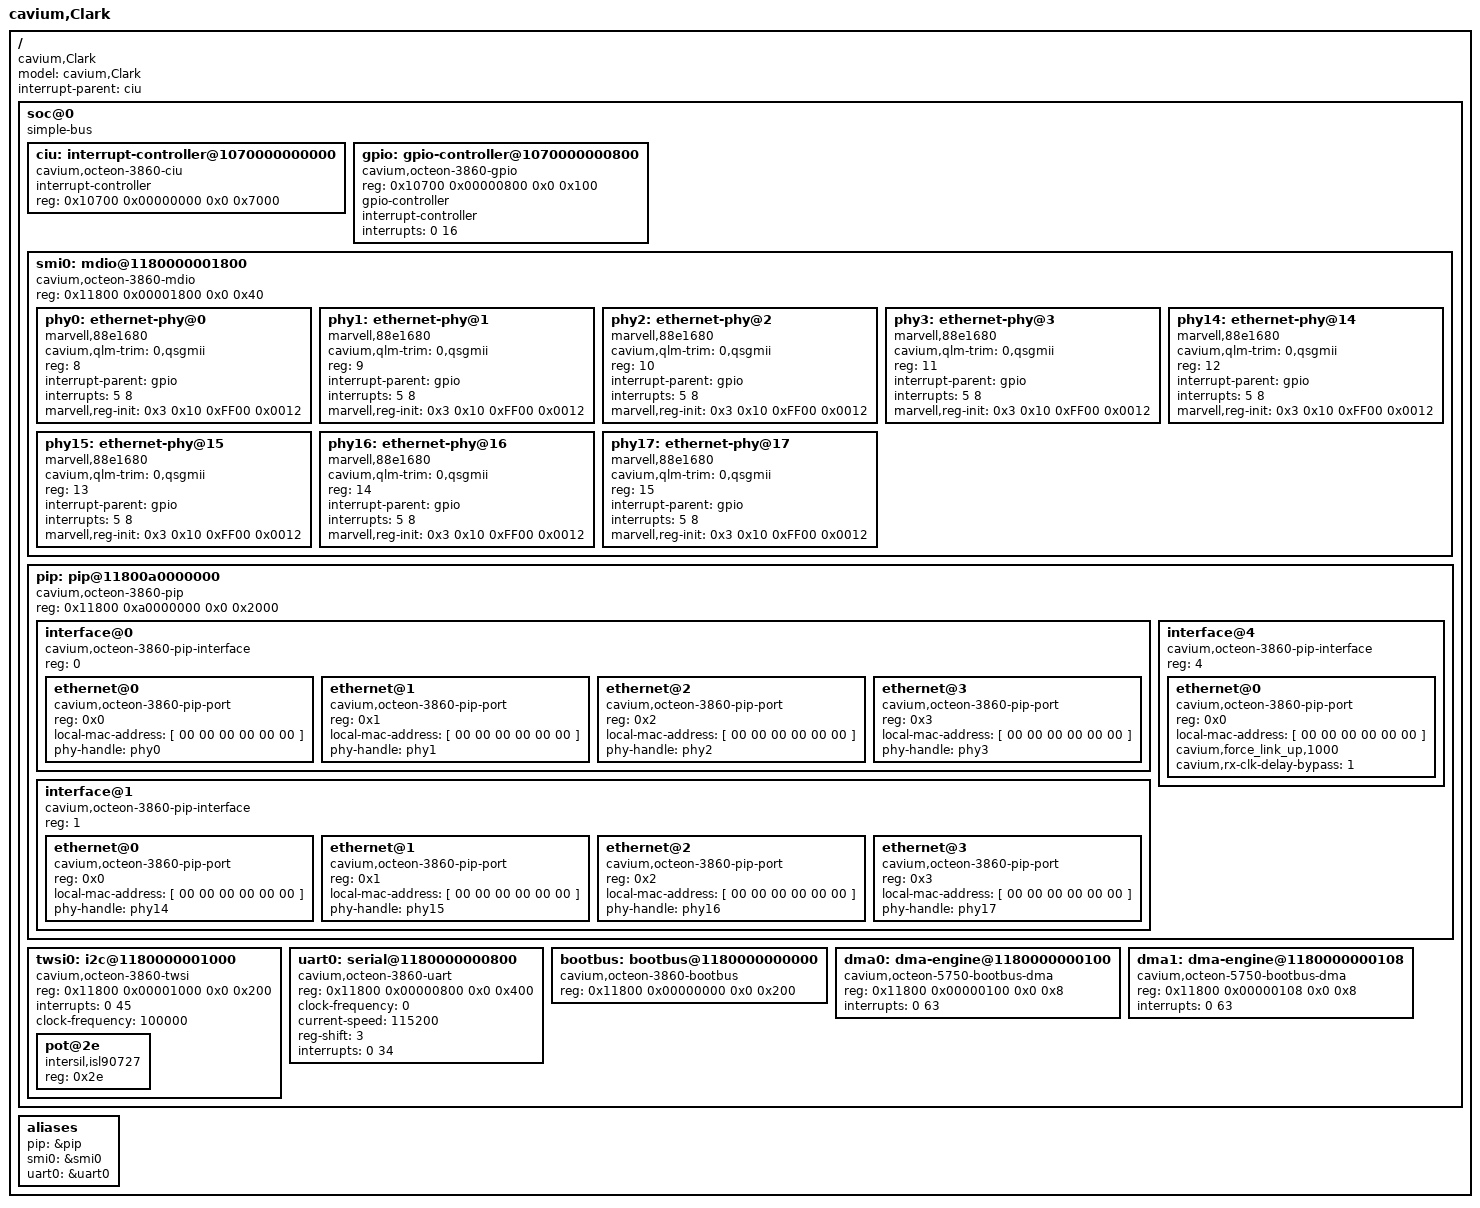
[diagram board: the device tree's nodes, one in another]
/dts-v1/;
/*
 * Cavium, Inc. Clark board
 */
/ {
	model = "cavium,Clark";
	compatible = "cavium,Clark";
	#address-cells = <2>;
	#size-cells = <2>;
	interrupt-parent = <&ciu>;

	soc@0 {
		compatible = "simple-bus";
		#address-cells = <2>;
		#size-cells = <2>;
		ranges; /* Direct mapping */

		ciu: interrupt-controller@1070000000000 {
			compatible = "cavium,octeon-3860-ciu";
			interrupt-controller;
			/* Interrupts are specified by two parts:
			 * 1) Controller register (0 or 1)
			 * 2) Bit within the register (0..63)
			 */
			#interrupt-cells = <2>;
			reg = <0x10700 0x00000000 0x0 0x7000>;
		};

		gpio: gpio-controller@1070000000800 {
			#gpio-cells = <2>;
			compatible = "cavium,octeon-3860-gpio";
			reg = <0x10700 0x00000800 0x0 0x100>;
			gpio-controller;
			/* Interrupts are specified by two parts:
			 * 1) GPIO pin number (0..15)
			 * 2) Triggering (1 - edge rising
			 *		  2 - edge falling
			 *		  4 - level active high
			 *		  8 - level active low)
			 */
			interrupt-controller;
			#interrupt-cells = <2>;
			/* The GPIO pins connect to 16 consecutive CUI bits */
			interrupts = <0 16>; /* <0 17> <0 18> <0 19>
				     <0 20> <0 21> <0 22> <0 23>
				     <0 24> <0 25> <0 26> <0 27>
				     <0 28> <0 29> <0 30> <0 31>; */
		};

		smi0: mdio@1180000001800 {
			compatible = "cavium,octeon-3860-mdio";
			#address-cells = <1>;
			#size-cells = <0>;
			reg = <0x11800 0x00001800 0x0 0x40>;

			phy0: ethernet-phy@0 {
				cavium,qlm-trim = "0,qsgmii";
				compatible = "marvell,88e1680";
				reg = <8>;
				interrupt-parent = <&gpio>;
				interrupts = <5 8>;	/* pin 5, active low */
				/* Configure the LEDs */
				marvell,reg-init = <0x3 0x10 0xFF00 0x0012>;
			};
			phy1: ethernet-phy@1 {
				cavium,qlm-trim = "0,qsgmii";
				compatible = "marvell,88e1680";
				reg = <9>;
				interrupt-parent = <&gpio>;
				interrupts = <5 8>;	/* pin 5, active low */
				marvell,reg-init = <0x3 0x10 0xFF00 0x0012>;
			};
			phy2: ethernet-phy@2 {
				cavium,qlm-trim = "0,qsgmii";
				compatible = "marvell,88e1680";
				reg = <10>;
				interrupt-parent = <&gpio>;
				interrupts = <5 8>;	/* pin 5, active low */
				marvell,reg-init = <0x3 0x10 0xFF00 0x0012>;
			};
			phy3: ethernet-phy@3 {
				cavium,qlm-trim = "0,qsgmii";
				compatible = "marvell,88e1680";
				reg = <11>;
				interrupt-parent = <&gpio>;
				interrupts = <5 8>;	/* pin 5, active low */
				marvell,reg-init = <0x3 0x10 0xFF00 0x0012>;
			};
                        phy14: ethernet-phy@14 {
				cavium,qlm-trim = "0,qsgmii";
				compatible = "marvell,88e1680";
				reg = <12>;
				interrupt-parent = <&gpio>;
				interrupts = <5 8>;	/* pin 5, active low */
				marvell,reg-init = <0x3 0x10 0xFF00 0x0012>;
			};
			phy15: ethernet-phy@15 {
				cavium,qlm-trim = "0,qsgmii";
				compatible = "marvell,88e1680";
				reg = <13>;
				interrupt-parent = <&gpio>;
				interrupts = <5 8>;	/* pin 5, active low */
				marvell,reg-init = <0x3 0x10 0xFF00 0x0012>;
			};
			phy16: ethernet-phy@16 {
				cavium,qlm-trim = "0,qsgmii";
				compatible = "marvell,88e1680";
				reg = <14>;
				interrupt-parent = <&gpio>;
				interrupts = <5 8>;	/* pin 5, active low */
				marvell,reg-init = <0x3 0x10 0xFF00 0x0012>;
			};
			phy17: ethernet-phy@17 {
				cavium,qlm-trim = "0,qsgmii";
				compatible = "marvell,88e1680";
				reg = <15>;
				interrupt-parent = <&gpio>;
				interrupts = <5 8>;	/* pin 5, active low */
				marvell,reg-init = <0x3 0x10 0xFF00 0x0012>;
			};

		};

		pip: pip@11800a0000000 {
			compatible = "cavium,octeon-3860-pip";
			#address-cells = <1>;
			#size-cells = <0>;
			reg = <0x11800 0xa0000000 0x0 0x2000>;

			interface@0 {
				compatible = "cavium,octeon-3860-pip-interface";
				#address-cells = <1>;
				#size-cells = <0>;
				reg = <0>; /* interface */

				ethernet@0 {
					compatible = "cavium,octeon-3860-pip-port";
					reg = <0x0>; /* Port */
					local-mac-address = [ 00 00 00 00 00 00 ];
					phy-handle = <&phy0>;
				};
				ethernet@1 {
					compatible = "cavium,octeon-3860-pip-port";
					reg = <0x1>; /* Port */
					local-mac-address = [ 00 00 00 00 00 00 ];
					phy-handle = <&phy1>;
				};
				ethernet@2 {
					compatible = "cavium,octeon-3860-pip-port";
					reg = <0x2>;
					local-mac-address = [ 00 00 00 00 00 00 ];
					phy-handle = <&phy2>;
				};
				ethernet@3 {
					compatible = "cavium,octeon-3860-pip-port";
					reg = <0x3>;
					local-mac-address = [ 00 00 00 00 00 00 ];
					phy-handle = <&phy3>;
				};
			};
			interface@1 {
				compatible = "cavium,octeon-3860-pip-interface";
				#address-cells = <1>;
				#size-cells = <0>;
				reg = <1>; /* interface */


				ethernet@0 {
					compatible = "cavium,octeon-3860-pip-port";
					reg = <0x0>;  /* Port */
					local-mac-address = [ 00 00 00 00 00 00 ];
					phy-handle = <&phy14>;
				};
				ethernet@1 {
					compatible = "cavium,octeon-3860-pip-port";
					reg = <0x1>;  /* Port */
					local-mac-address = [ 00 00 00 00 00 00 ];
					phy-handle = <&phy15>;
				};
				ethernet@2 {
					compatible = "cavium,octeon-3860-pip-port";
					reg = <0x2>;
					local-mac-address = [ 00 00 00 00 00 00 ];
					phy-handle = <&phy16>;
				};
				ethernet@3 {
					compatible = "cavium,octeon-3860-pip-port";
					reg = <0x3>;
					local-mac-address = [ 00 00 00 00 00 00 ];
					phy-handle = <&phy17>;
				};
			};
                      interface@4 {
                              compatible = "cavium,octeon-3860-pip-interface";
                              #address-cells = <1>;
                              #size-cells = <0>;
                              reg = <4>; /* interface */

                              ethernet@0 {
                                      compatible = "cavium,octeon-3860-pip-port";
                                      reg = <0x0>; /* Port */
                                      local-mac-address = [ 00 00 00 00 00 00 ];
				      /* Force link to always be up */
				      cavium,force_link_up,1000;
				      cavium,rx-clk-delay-bypass = <1>;
                              };
                      };
                };

		twsi0: i2c@1180000001000 {
			#address-cells = <1>;
			#size-cells = <0>;
			compatible = "cavium,octeon-3860-twsi";
			reg = <0x11800 0x00001000 0x0 0x200>;
			interrupts = <0 45>;
			clock-frequency = <100000>;

			pot@2e {
				compatible = "intersil,isl90727";
				reg = <0x2e>;
			};
		};

		uart0: serial@1180000000800 {
			compatible = "cavium,octeon-3860-uart","ns16550";
			reg = <0x11800 0x00000800 0x0 0x400>;
			clock-frequency = <0>;
			current-speed = <115200>;
			reg-shift = <3>;
			interrupts = <0 34>;
		};

		bootbus: bootbus@1180000000000 {
			compatible = "cavium,octeon-3860-bootbus";
			reg = <0x11800 0x00000000 0x0 0x200>;
			/* The chip select number and offset */
			#address-cells = <2>;
			/* The size of the chip select region */
			#size-cells = <1>;
			ranges = <0 0  0x10000 0x10000000  0>,
				 <1 0  0x10000 0x20000000  0>,
				 <2 0  0x10000 0x30000000  0>,
				 <3 0  0x10000 0x40000000  0>,
				 <4 0  0x10000 0x50000000  0>,
				 <5 0  0x10000 0x60000000  0>,
				 <6 0  0x10000 0x70000000  0>,
				 <7 0  0x10000 0x80000000  0>;
		};

		dma0: dma-engine@1180000000100 {
			compatible = "cavium,octeon-5750-bootbus-dma";
			reg = <0x11800 0x00000100 0x0 0x8>;
			interrupts = <0 63>;
		};
		dma1: dma-engine@1180000000108 {
			compatible = "cavium,octeon-5750-bootbus-dma";
			reg = <0x11800 0x00000108 0x0 0x8>;
			interrupts = <0 63>;
		};
	};

	aliases {
		pip = &pip;
		smi0 = &smi0;
		uart0 = &uart0;
	};
 };
